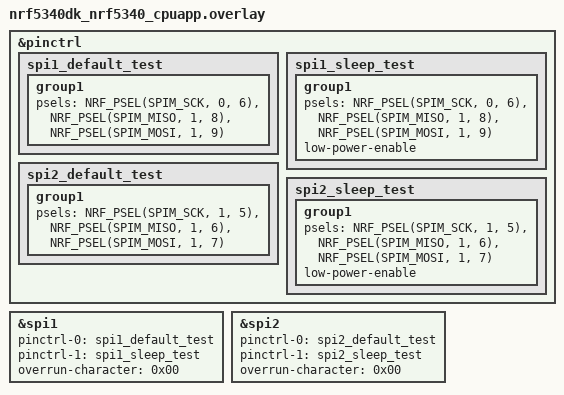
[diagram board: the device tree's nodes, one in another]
/*
 * Copyright (c) 2026 Nordic Semiconductor ASA
 *
 * SPDX-License-Identifier: LicenseRef-Nordic-5-Clause
 */

&pinctrl {
	spi1_default_test: spi1_default_test {
		group1 {
			psels = <NRF_PSEL(SPIM_SCK, 0, 6)>,
				<NRF_PSEL(SPIM_MISO, 1, 8)>,
				<NRF_PSEL(SPIM_MOSI, 1, 9)>;
		};
	};

	spi1_sleep_test: spi1_sleep_test {
		group1 {
			psels = <NRF_PSEL(SPIM_SCK, 0, 6)>,
				<NRF_PSEL(SPIM_MISO, 1, 8)>,
				<NRF_PSEL(SPIM_MOSI, 1, 9)>;
			low-power-enable;
		};
	};

	spi2_default_test: spi2_default_test {
		group1 {
			psels = <NRF_PSEL(SPIM_SCK, 1, 5)>,
				<NRF_PSEL(SPIM_MISO, 1, 6)>,
				<NRF_PSEL(SPIM_MOSI, 1, 7)>;
		};
	};

	spi2_sleep_test: spi2_sleep_test {
		group1 {
			psels = <NRF_PSEL(SPIM_SCK, 1, 5)>,
				<NRF_PSEL(SPIM_MISO, 1, 6)>,
				<NRF_PSEL(SPIM_MOSI, 1, 7)>;
			low-power-enable;
		};
	};
};

/delete-node/ &mx25r64;

&spi1 {
	status = "okay";
	pinctrl-0 = <&spi1_default_test>;
	pinctrl-1 = <&spi1_sleep_test>;
	pinctrl-names = "default", "sleep";
	overrun-character = <0x00>;
};

&spi2 {
	status = "okay";
	pinctrl-0 = <&spi2_default_test>;
	pinctrl-1 = <&spi2_sleep_test>;
	pinctrl-names = "default", "sleep";
	overrun-character = <0x00>;
};
